AUTOSAR XML (schema 4-2-2)
package /COM_SWC
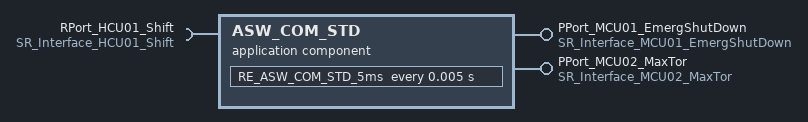
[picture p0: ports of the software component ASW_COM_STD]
  application sw component type ASW_COM_STD
    provide port PPort_MCU01_EmergShutDown: provided-interface=SR_Interface_MCU01_EmergShutDown
    provide port PPort_MCU02_MaxTor: provided-interface=SR_Interface_MCU02_MaxTor
    require port RPort_HCU01_Shift: nonqueued-receiver-com-spec{alive-timeout=0.3, data-element=HCU01_Shift}, required-interface=SR_Interface_HCU01_Shift
    behavior IB_ASW_COM_STD
      timing event TE_ASW_COM_STD_5ms: start-on-event=RE_ASW_COM_STD_5ms, period=0.005
      runnable RE_ASW_COM_STD_5ms
